VERSION ""

NS_ :

BS_:

BU_: VCU MOTOR BMS DEBUG

// ============================================
// Message Definitions
// ============================================

// 0x201: Motor Torque Command (VCU → MOTOR)
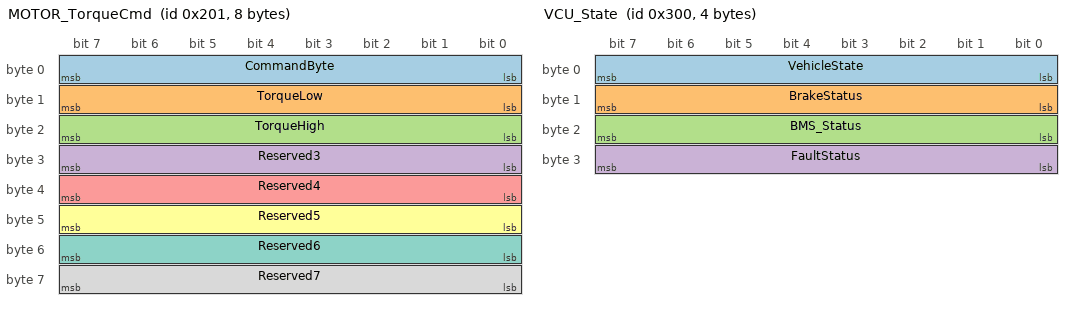
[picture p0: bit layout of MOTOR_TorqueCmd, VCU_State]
BO_ 513 MOTOR_TorqueCmd: 8 VCU
 SG_ CommandByte : 0|8@1+ (1,0) [0|255] "" MOTOR
 SG_ TorqueLow : 8|8@1+ (1,0) [0|255] "" MOTOR
 SG_ TorqueHigh : 16|8@1+ (1,0) [0|255] "" MOTOR
 SG_ Reserved3 : 24|8@1+ (1,0) [0|255] "" MOTOR
 SG_ Reserved4 : 32|8@1+ (1,0) [0|255] "" MOTOR
 SG_ Reserved5 : 40|8@1+ (1,0) [0|255] "" MOTOR
 SG_ Reserved6 : 48|8@1+ (1,0) [0|255] "" MOTOR
 SG_ Reserved7 : 56|8@1+ (1,0) [0|255] "" MOTOR

// 0x300: Debug State Message (VCU → DEBUG)
BO_ 768 VCU_State: 4 VCU
 SG_ VehicleState : 0|8@1+ (1,0) [0|3] "" DEBUG
 SG_ BrakeStatus : 8|8@1+ (1,0) [0|1] "" DEBUG
 SG_ BMS_Status : 16|8@1+ (1,0) [0|1] "" DEBUG
 SG_ FaultStatus : 24|8@1+ (1,0) [0|1] "" DEBUG

// 0x301: Debug Pedals Message (VCU → DEBUG)
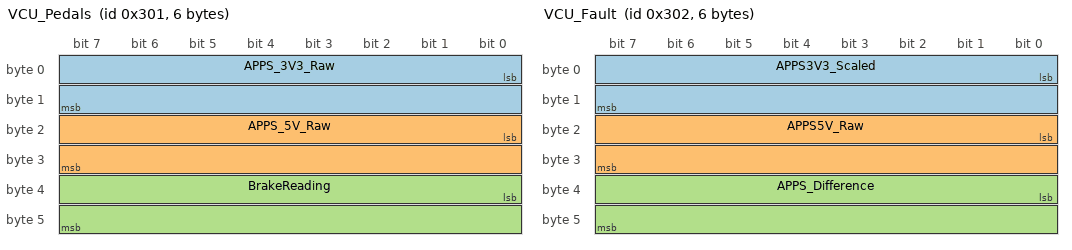
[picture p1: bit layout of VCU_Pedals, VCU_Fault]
BO_ 769 VCU_Pedals: 6 VCU
 SG_ APPS_3V3_Raw : 0|16@1+ (1,0) [0|1023] "raw" DEBUG
 SG_ APPS_5V_Raw : 16|16@1+ (1,0) [0|1023] "raw" DEBUG
 SG_ BrakeReading : 32|16@1+ (1,0) [0|1023] "raw" DEBUG

// 0x302: Debug Fault Message (VCU → DEBUG)
BO_ 770 VCU_Fault: 6 VCU
 SG_ APPS3V3_Scaled : 0|16@1+ (1,0) [0|1023] "scaled" DEBUG
 SG_ APPS5V_Raw : 16|16@1+ (1,0) [0|1023] "raw" DEBUG
 SG_ APPS_Difference : 32|16@1+ (1,0) [0|1023] "units" DEBUG

// 0x186040F3: BMS Status Message (BMS → VCU)
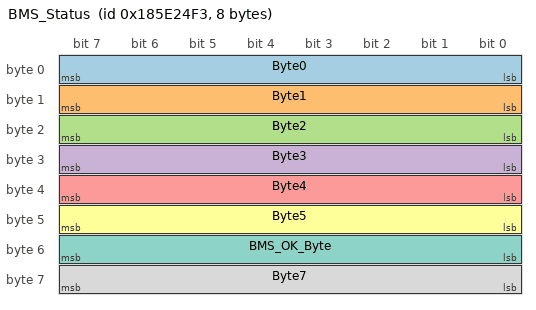
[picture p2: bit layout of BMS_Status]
BO_ 408823027 BMS_Status: 8 BMS
 SG_ Byte0 : 0|8@1+ (1,0) [0|255] "" VCU
 SG_ Byte1 : 8|8@1+ (1,0) [0|255] "" VCU
 SG_ Byte2 : 16|8@1+ (1,0) [0|255] "" VCU
 SG_ Byte3 : 24|8@1+ (1,0) [0|255] "" VCU
 SG_ Byte4 : 32|8@1+ (1,0) [0|255] "" VCU
 SG_ Byte5 : 40|8@1+ (1,0) [0|255] "" VCU
 SG_ BMS_OK_Byte : 48|8@1+ (1,0) [0|255] "" VCU  // This is data[6]
 SG_ Byte7 : 56|8@1+ (1,0) [0|255] "" VCU

// ============================================
// Value Tables (Human-readable values)
// ============================================

// Vehicle State values
VAL_ 768 VCU_State.VehicleState 3 "DRIVE" 2 "BUZZIN" 1 "STARTIN" 0 "INIT";

// Boolean status values
VAL_ 768 VCU_State.BrakeStatus 1 "PRESSED" 0 "RELEASED";
VAL_ 768 VCU_State.BMS_Status 1 "OK" 0 "NOT_OK";
VAL_ 768 VCU_State.FaultStatus 1 "FAULT" 0 "NO_FAULT";

// BMS OK Byte values (for Byte6)
VAL_ 408823027 BMS_Status.BMS_OK_Byte 0x50 "BMS_OK" 0x00 "BMS_NOT_OK";

// ============================================
// Message Comments
// ============================================

CM_ BO_ 513 "Motor torque command from VCU to motor controller. CommandByte=0x90 indicates torque command. Torque value is signed 16-bit little endian in bytes 1-2.";
CM_ BO_ 768 "VCU state information for debugging. Sent every 100ms.";
CM_ BO_ 769 "Raw pedal readings for debugging. APPS_3V3_Raw is unscaled 0-675 reading.";
CM_ BO_ 770 "APPS fault information. Sent when APPS sensors differ by >10%.";
CM_ BO_ 408823027 "BMS status message. VCU checks Byte6 (BMS_OK_Byte) for 0x50 to confirm BMS is ready.";

// ============================================
// Signal Comments
// ============================================

CM_ SG_ 513 CommandByte "Always 0x90 for torque command";
CM_ SG_ 513 TorqueLow "Low byte of torque value (signed 16-bit)";
CM_ SG_ 513 TorqueHigh "High byte of torque value (signed 16-bit)";
CM_ SG_ 768 VehicleState "Current VCU state: 0=INIT, 1=STARTIN, 2=BUZZIN, 3=DRIVE";
CM_ SG_ 768 BrakeStatus "Brake pedal status: 0=Released, 1=Pressed (>10% depression)";
CM_ SG_ 768 BMS_Status "BMS status from last received message";
CM_ SG_ 768 FaultStatus "APPS fault status: 0=No fault, 1=Fault detected";
CM_ SG_ 769 APPS_3V3_Raw "Raw APPS 3.3V sensor reading (0-675)";
CM_ SG_ 769 APPS_5V_Raw "Raw APPS 5V sensor reading (0-1023)";
CM_ SG_ 769 BrakeReading "Raw brake sensor reading (0-1023)";
CM_ SG_ 770 APPS3V3_Scaled "APPS 3.3V reading scaled to 5V range (0-1023)";
CM_ SG_ 770 APPS5V_Raw "APPS 5V raw reading (0-1023)";
CM_ SG_ 770 APPS_Difference "Absolute difference between scaled APPS readings";
CM_ SG_ 408823027 BMS_OK_Byte "Byte 6 of BMS message. 0x50 indicates BMS is ready for operation";
